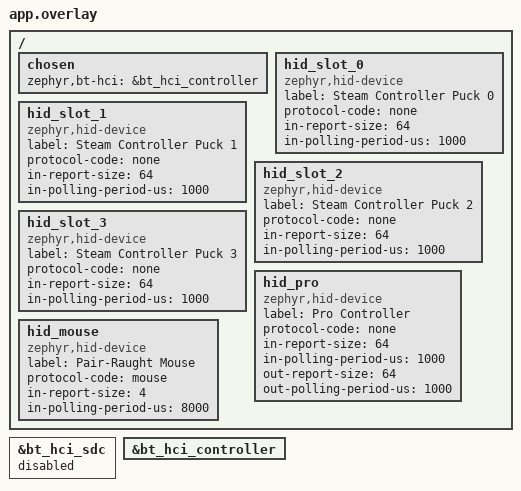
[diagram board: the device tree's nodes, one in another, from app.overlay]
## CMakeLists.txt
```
cmake_minimum_required(VERSION 3.20.0)

find_package(Zephyr REQUIRED HINTS $ENV{ZEPHYR_BASE})
project(switch2_ll)

target_sources(app PRIVATE src/main.c src/switch2_gatt.c src/switch2_memory.c
                          src/switch2_store.c src/rf_radio.c
                          src/puck_usb.c src/puck_hid.c
                          src/rf_link.c src/puck_input.c src/switch_pro.c
                          src/switch_pro_usb.c src/puck_trace.c
                          src/puck_settings.c
                          src/puck_rumble.c src/puck_webdisk.c
                          src/puck_melody.c)

# The console's LL_ENC_REQ carries EDIV=0/Rand=0 -- an out-of-band key agreed
# over GATT, not via SMP -- so the derived LTK has to be pushed straight into
# the host's key store. bt_keys_get_addr()/bt_keys_add_type() are host-internal
# with no public equivalent, so the host directory is on the include path.
# Reassess if a supported API for injecting an out-of-band LTK ever appears.
target_include_directories(app PRIVATE $ENV{ZEPHYR_BASE}/subsys/bluetooth/host)
```

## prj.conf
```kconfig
# Milestone 1: prove the nRF52840 can ACCEPT and HOLD the Switch 2's 5 ms
# connection interval. Nothing else -- no GATT server, no protocol.
#
# The Switch 2 opens controller connections with a CONNECT_IND carrying
# interval=4 (5.00 ms). That is below the Bluetooth spec floor of 6 units
# (7.5 ms), so Nordic's closed SoftDevice silently refuses to join: measured
# on air, 213 CONNECT_INDs at interval=4 went completely unanswered while the
# single interval=12 (15 ms) offer connected and ran for 33 s.
#
# Zephyr's software controller applies the same rule, but in source we can
# edit -- see patches/ull_peripheral-accept-5ms.patch.

CONFIG_BT=y
CONFIG_BT_PERIPHERAL=y
CONFIG_BT_DEVICE_NAME="Joy-Con 2 (R)"

# ---- Attribute table -----------------------------------------------------
# The console writes 0x000F and 0x0010 by hardcoded handle, so the table's
# POSITION matters as much as its content -- see src/switch2_gatt.c.
#
# CONFIG_BT_GATT_CACHING adds Database Hash / Client Supported Features
# attributes ahead of ours and would shift every handle. Off, so the layout is
# ours to control and stays stable across boots.
CONFIG_BT_GATT_CACHING=n

# Services are registered at runtime so the ORDER is ours, not the linker's --
# measured: static definition put the bd28x service first and threw the report
# channel seven handles off. See the comment above switch2_gatt_init().
CONFIG_BT_GATT_DYNAMIC_DB=y

# ---- Encryption ----------------------------------------------------------
# SMP is enabled for its KEY STORE, not to do any pairing.
#
# The console never runs an SMP pairing over this link. Its LL_ENC_REQ carries
# EDIV=0 and Rand=0 -- an out-of-band key -- so the GATT PAIR ceremony IS the
# key agreement, and we derive the LTK ourselves from the 0x15/0x04 exchange.
# What Zephyr provides is bt_smp_request_ltk(), which answers the controller's
# LTK request from conn->le.keys when EDIV and Rand are both zero and the key is
# typed BT_KEYS_LTK_P256. So the derived key is injected into that store the
# moment it exists -- see derive_link_key() in switch2_gatt.c.
#
# Without this the handshake completes in full and the link then dies with
# reason=0x22 (LL Response Timeout), because the console asks to encrypt and
# nothing can answer.
CONFIG_BT_SMP=y
CONFIG_BT_MAX_PAIRED=1
CONFIG_BT_SETTINGS=n

# ---- Link-key persistence -------------------------------------------------
# The Switch 2 drops dock power when it sleeps, and the puck is powered from
# that port, so EVERY wake attempt starts from a cold boot. The console does not
# re-pair on a reconnect -- it sends LL_ENC_REQ expecting the key it stored at
# registration. Measured without persistence: the console finds us on its own,
# opens a 5 ms link, and we answer LL_REJECT_EXT_IND error 0x06 (PIN or Key
# Missing), after which it terminates with 0x13, in a loop.
#
# NVS on the board's 32 KB storage_partition (0xec000). BT_SETTINGS stays off:
# we are not using Zephyr's bonding, only storing the one out-of-band key --
# see src/switch2_store.c.
CONFIG_FLASH=y
CONFIG_FLASH_MAP=y
CONFIG_NVS=y
CONFIG_MPU_ALLOW_FLASH_WRITE=y
# REQUIRED, and its absence is silent: nvs_mount() needs the sector size, which
# switch2_store.c asks for with flash_get_page_info_by_offs(). Without page
# layout support that call returns -ENOTSUP, the mount fails, and the only
# symptom is that nothing is ever persisted.
CONFIG_FLASH_PAGE_LAYOUT=y

# ATT MTU 512 -- matched to the old stack, which is ground truth for a link the
# console was willing to proceed on.
#
# The console sends Exchange MTU Request with Client Rx MTU = 512. The old
# Bluefruit build answered 512 and the console immediately began service
# discovery (Read By Group Type 0x0001-0xFFFF). This build answered 247 and the
# console sent nothing further -- measured, the MTU exchange was the LAST ATT
# traffic of the entire connection, two frames and then silence.
#
# BT_BUF_ACL_RX_SIZE must cover the full L2CAP SDU plus its 4-byte header,
# because reassembly needs one contiguous buffer; TX is fragmented to the
# controller's data length so it does not.
CONFIG_BT_L2CAP_TX_MTU=512
CONFIG_BT_BUF_ACL_RX_SIZE=516
CONFIG_BT_BUF_ACL_TX_SIZE=251
CONFIG_BT_ATT_PREPARE_COUNT=2

# Use Zephyr's OPEN software link layer, not Nordic's SoftDevice Controller.
# The SDC is a binary blob and enforces the 7.5 ms floor where we cannot reach
# it. Selection is done in the devicetree overlay; this is belt and braces.
CONFIG_BT_LL_SW_SPLIT=y

# The console never subscribes anything in this test, but it does run a link
# layer feature exchange immediately after CONNECT_IND -- that exchange
# completing is the pass condition.
CONFIG_BT_CTLR_DATA_LENGTH_MAX=251
CONFIG_BT_CTLR_PHY_2M=y

# Let the CONSOLE choose the connection interval -- do not negotiate.
#
# Zephyr defaults to BT_PERIPHERAL_PREF_MIN_INT=24 (30 ms) and automatically
# asks the central for it shortly after connecting. Measured 2026-08-15: the
# Switch 2 connected at interval=12 (15 ms) and then ACCEPTED our 30 ms request
# at +5 s. That is the opposite of what this test needs -- the whole point is to
# see the console push its own 5 ms interval at us and find out whether the
# patched link layer takes it. The Arduino firmware did no negotiation at all,
# and that is the configuration in which the console was observed demanding
# 5 ms, so match it.
CONFIG_BT_GAP_AUTO_UPDATE_CONN_PARAMS=n

# USB CDC console: DO NOT enable a USB stack here. The board's
# Kconfig.defconfig already sources boards/common/usb/Kconfig.cdc_acm_serial
# which selects USB_DEVICE_STACK_NEXT and initialises CDC ACM at boot. Setting
# CONFIG_USB_DEVICE_STACK=y as well builds BOTH stacks and the link fails with
# "multiple definition of __device_dts_ord_104".
#
# That file also sets LOG_PROCESS_THREAD_STARTUP_DELAY_MS=4000, so the log
# waits for the port to enumerate before emitting.

# CRITICAL for this board. The upstream promicro_nrf52840 board definition
# defaults to CONFIG_CLOCK_CONTROL_NRF_K32SRC_XTAL, i.e. an external 32.768 kHz
# crystal -- which these cheap Pro Micro clones do not have. With no LFCLK the
# BLE controller can never schedule a radio event, so bt_enable() and
# bt_le_adv_start() both return success and NOTHING is transmitted. Measured:
# firmware alive and heartbeating over USB, host reporting
# an identity and "advertising ... wake mode", while
# a 30 s sniffer survey saw six other advertisers and zero packets from us.
# The internal RC oscillator costs accuracy (500 ppm vs ~20 ppm) but works.
CONFIG_CLOCK_CONTROL_NRF_K32SRC_RC=y
CONFIG_CLOCK_CONTROL_NRF_K32SRC_500PPM=y

# ---- USB: we are a Valve Steam Controller dongle -------------------------
# The board's cdc_acm_serial helper builds a USB device automatically so the
# console works with no app code, but it hardcodes its own VID/PID and, in its
# own words, "only registers the first CDC-ACM instance" and is "intended for
# use only in applications where no other USB features are required". We need
# 28DE:1304 and five interfaces, so it is turned off and src/puck_usb.c builds
# the device instead -- including the CDC console, which would otherwise vanish.
# TEMPORARILY REVERTED to the board's auto-init while the custom device is
# debugged. Building our own context (28DE:1304 + 4 HID + CDC) made the board
# enumerate as "Unknown USB Device (Port Reset Failed)" -- no console, and
# recovery costs a physical double-tap on reset. Debugging that blind is not
# worth a button press per guess, so the console comes first and the composite
# device gets rebuilt against a working one.
CONFIG_CDC_ACM_SERIAL_INITIALIZE_AT_BOOT=n
CONFIG_USBD_HID_SUPPORT=y

CONFIG_LOG=y
CONFIG_PRINTK=y

# Deliberately NOT CONFIG_LOG_MODE_IMMEDIATE. Immediate mode logs synchronously
# from the calling context, which on a CDC console blocks when the host is slow
# or absent -- that is exactly the 84 ms main-loop stall that distorted every
# measurement taken with the Arduino firmware. Deferred logging keeps the
# radio's timing honest, which matters more here than log latency.
#
# BUT take printk back out of the deferred path. CONFIG_LOG_PRINTK defaults to y,
# which routes printk() through the very same buffer, so "use printk instead of
# LOG_INF for diagnostics" bought nothing: measured 2026-08-15, an entire boot's
# worth of printk output AND five heartbeats were discarded, hiding a hard
# bt_le_adv_start() -ENOMEM behind a log that jumped from 0.003 s to 30 s. With
# this off, printk writes straight to the console driver and cannot be dropped.
# It blocks, so keep it to diagnostics and out of the radio's hot path.
CONFIG_LOG_PRINTK=n

# 1024 bytes is roughly ten messages -- less than one boot. The messages that
# matter here (bt_hci_core's "opcode 0x%04x status 0x%02x") arrive while USB is
# still enumerating, so the buffer has to survive the whole startup backlog.
CONFIG_LOG_BUFFER_SIZE=4096

# Real console input. uart_poll_in() never sees a byte on a CDC ACM console
# (interrupt driven), which silently broke the reboot-to-bootloader key.
CONFIG_CONSOLE_SUBSYS=y
CONFIG_CONSOLE_GETCHAR=y

# console_getchar() defaults to a SIXTEEN byte ring, which is fine for single
# keypresses and silently loses characters the moment anything types a line.
# The config protocol sends whole commands at once -- "$set mouse.speed 8" is
# nineteen characters -- and the overflow showed up as commands that simply
# never executed, with the tail of one line turning up glued to the next.
# Zephyr own help text names the case: "you may need to increase it e.g. to
# support large host-side clipboard pastes".
CONFIG_CONSOLE_GETCHAR_BUFSIZE=256

# sys_reboot() -- used to reboot into a one-shot armed USB attempt (TEMPORARY,
# see the scaffolding note in switch2_store.c).
CONFIG_REBOOT=y

# The config page as a USB drive, in dongle mode only. The volume is
# synthesised per sector by puck_webdisk.c, so no disk driver and no
# filesystem are needed -- and no RAM is spent on either.
CONFIG_USBD_MSC_CLASS=y
CONFIG_DISK_ACCESS=y
```

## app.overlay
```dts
/*
 * Select Zephyr's open software link layer instead of Nordic's SoftDevice
 * Controller.
 *
 * nrf52840.dtsi ships with:
 *     chosen { zephyr,bt-hci = &bt_hci_sdc; }
 *     bt_hci_sdc        (nordic,bt-hci-sdc)         status = "okay"
 *     bt_hci_controller (zephyr,bt-hci-ll-sw-split) status = "disabled"
 *
 * The SDC is a binary blob, so its 7.5 ms connection-interval floor cannot be
 * relaxed. The software controller is source we can patch, which is the entire
 * reason for this port.
 */

/ {
	chosen {
		zephyr,bt-hci = &bt_hci_controller;
	};
};

&bt_hci_sdc {
	status = "disabled";
};

&bt_hci_controller {
	status = "okay";
};

/*
 * The Valve dongle's four HID interfaces.
 *
 * A real Steam Controller dongle exposes ONE HID interface per bond slot, and
 * Steam treats each as an independent controller -- interface N owns slot N.
 * That is also how pairing happens: Steam drives the control channel over
 * feature reports (report IDs 0x01/0x02, 63 bytes) on these interfaces, and the
 * resulting bond record is what the RF layer later beacons for. There is no
 * over-the-air pairing, so without these four interfaces no controller can ever
 * be bonded.
 *
 * in-report-size 64 covers the largest input report in PUCK_HID_DESC (0x45 is
 * 0x2D=45 bytes, plus the report ID). 1 ms polling matches the dongle, which
 * Steam's input path expects.
 */
/ {
	hid_slot_0: hid_slot_0 {
		compatible = "zephyr,hid-device";
		label = "Steam Controller Puck 0";
		protocol-code = "none";
		in-report-size = <64>;
		in-polling-period-us = <1000>;
	};

	hid_slot_1: hid_slot_1 {
		compatible = "zephyr,hid-device";
		label = "Steam Controller Puck 1";
		protocol-code = "none";
		in-report-size = <64>;
		in-polling-period-us = <1000>;
	};

	hid_slot_2: hid_slot_2 {
		compatible = "zephyr,hid-device";
		label = "Steam Controller Puck 2";
		protocol-code = "none";
		in-report-size = <64>;
		in-polling-period-us = <1000>;
	};

	hid_slot_3: hid_slot_3 {
		compatible = "zephyr,hid-device";
		label = "Steam Controller Puck 3";
		protocol-code = "none";
		in-report-size = <64>;
		in-polling-period-us = <1000>;
	};

	/*
	 * The Pro Controller interface, used INSTEAD of the four above when the
	 * puck boots in Pro Controller mode.
	 *
	 * It needs an interrupt OUT endpoint, which the Steam interfaces do not
	 * have: the console sends its handshake and subcommands (reports 0x01,
	 * 0x10, 0x80) on the OUT pipe, and without one they would only ever
	 * arrive as control-pipe SET_REPORTs -- which is not where a real Pro
	 * Controller receives them.
	 *
	 * 1 ms polling matches what the Arduino build sets (setPollInterval(1)).
	 */
	hid_pro: hid_pro {
		compatible = "zephyr,hid-device";
		label = "Pro Controller";
		protocol-code = "none";
		in-report-size = <64>;
		in-polling-period-us = <1000>;
		out-report-size = <64>;
		out-polling-period-us = <1000>;
	};

	/*
	 * A plain boot-protocol MOUSE, carried alongside the Pro Controller.
	 *
	 * The Switch 2 supports USB mice, so the trackpads can drive one -- but
	 * whether the console still binds a Pro Controller that has a mouse
	 * sitting beside it is UNKNOWN. Adding an interface to a working device
	 * is exactly what COMBO did, and Steam misbehaved with it. A console has
	 * no reason to claim a mouse the way Steam claimed a gamepad, but that
	 * was true of Steam too until it was tried.
	 *
	 * 4-byte report: buttons, dx, dy, wheel.
	 */
	hid_mouse: hid_mouse {
		compatible = "zephyr,hid-device";
		label = "Pair-Raught Mouse";
		protocol-code = "mouse";
		in-report-size = <4>;
		in-polling-period-us = <8000>;
	};
};
```

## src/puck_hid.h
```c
/*
 * The Valve dongle HID interfaces. One per bond slot, and the path Steam
 * pairs a Steam Controller through.
 */

#ifndef PUCK_HID_H
#define PUCK_HID_H

/* Register the report descriptor and callbacks on every HID interface. MUST run
 * before usbd_init(): until this is called the HID class contributes no
 * interface descriptor and device assembly fails with -EINVAL.
 */
int puck_hid_register_all(void);

/*
 * Reload the Steam bonds from NVS. Needed in BOTH USB modes: the RF layer
 * derives each slot session address from its bond, so without this the puck
 * never beacons and no controller input arrives, in Pro Controller mode that
 * looks like a pad that enumerates perfectly with every button dead.
 */
void puck_hid_restore_bonds(void);

/*
 * This slot's Steam bond record, or NULL if the slot is empty.
 *
 * [0..4] proteus uuid, [4..8] ibex uuid, [8..24] the controller's 16-byte
 * serial. The RF layer needs the two uuids: they go in the E1 beacon so the
 * controller can recognise a puck it is bonded to, and the ibex uuid seeds this
 * slot's unique session address.
 */
const uint8_t *puck_hid_bond(int slot);

/*
 * Push one input report to Steam on this slot's interface.
 *
 * Steam decides a controller is CONNECTED by receiving these, not by the 0xB4
 * connection-state answer alone, so nothing appears online until the RF layer
 * starts forwarding the controller's 0x45/0x42 reports through here.
 */
int puck_hid_send_input(int slot, uint8_t rid, const uint8_t *data,
			uint16_t len);

/*
 * Push each slot's connection state to Steam (report 0x79). Call periodically.
 *
 * Steam does not notice a controller going away by itself. Without this it
 * keeps listing one that has been switched off, and a later re-pair then shows
 * up as a SECOND controller alongside the stale entry.
 */
void puck_hid_conn_task(void);

/*
 * Per-slot state of the outgoing report path, whether the host is draining
 * this interface, and how many reports were dropped because it was not.
 */
void puck_hid_dump_tx(void);

/* A power-off was relayed to this slot (the Steam+Y chord), so force a clean
 * disconnect and hold it through the controller's post-off report tail.
 */
void puck_hid_note_power_off(int slot);

#endif /* PUCK_HID_H */
```

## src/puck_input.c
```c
/*
 * Decode the Steam Controller's input report.
 *
 * Field offsets are relative to rep[2], the buttons' low byte, matching the
 * Arduino build's s16off()/u16off() decoders so the two firmwares read the same
 * wire format the same way:
 *
 *   +0   buttons u32 LE
 *   +4   left trigger  u16
 *   +6   right trigger u16
 *   +8   left stick  X s16   +10  left stick  Y s16
 *   +12  right stick X s16   +14  right stick Y s16
 *   +22  right pad X s16     +24  right pad Y s16
 *   (IMU: accel @0x22, gyro @0x28 from the report start)
 *
 * Report id 0x45 is the legacy form and 0x42 the one shipped in the mid-2026
 * controller update; bytes [0..45] are byte-for-byte identical between them, so
 * both decode through this one path.
 */

#include <zephyr/kernel.h>
#include <string.h>

#include "puck_input.h"

static struct puck_input g_in[PUCK_HID_SLOTS];

static int s16off(const uint8_t *r, int off)
{
	int v = r[2 + off] | (r[2 + off + 1] << 8);

	return (v & 0x8000) ? v - 0x10000 : v;
}

static int u16off(const uint8_t *r, int off)
{
	return r[2 + off] | (r[2 + off + 1] << 8);
}

/*
 * The controller's trigger u16 tops out near HALF scale (~0x8000) on a full
 * pull, so a straight >>8 reads only ~0x80 and the host sees a half-pressed
 * trigger. Scale by two and saturate.
 */
static uint8_t trig_u8(int v16)
{
	int v = v16 >> 7;

	return (uint8_t)(v > 255 ? 255 : v);
}

void puck_input_update(int slot, const uint8_t *rep)
{
	struct puck_input *in;

	if (slot < 0 || slot >= PUCK_HID_SLOTS) {
		return;
	}
	in = &g_in[slot];

	in->buttons = (uint32_t)rep[2] | ((uint32_t)rep[3] << 8) |
		      ((uint32_t)rep[4] << 16) | ((uint32_t)rep[5] << 24);

	in->lt = trig_u8(u16off(rep, 4));
	in->rt = trig_u8(u16off(rep, 6));

	in->lx = (int16_t)s16off(rep, 8);
	in->ly = (int16_t)s16off(rep, 10);
	in->rx = (int16_t)s16off(rep, 12);
	in->ry = (int16_t)s16off(rep, 14);

	/* Right trackpad, absolute. Only meaningful while TB_RPADT says a
	 * finger is down. The coordinates hold their last value on release,
	 * so anything reading them must gate on the touch bit or it will see a
	 * jump the next time a finger lands somewhere else.
	 */
	in->rpx = (int16_t)s16off(rep, 22);
	in->rpy = (int16_t)s16off(rep, 24);

	/* IMU: accel at 32/34/36, gyro at 38/40/42 (PROTOCOL.md section 8, via
	 * the Arduino build imuFrom45). Raw sensor frame, whoever consumes it
	 * does the axis permutation, because each output mode wants a different
	 * one.
	 */
	in->ax = (int16_t)s16off(rep, 32);
	in->ay = (int16_t)s16off(rep, 34);
	in->az = (int16_t)s16off(rep, 36);
	in->gx = (int16_t)s16off(rep, 38);
	in->gy = (int16_t)s16off(rep, 40);
	in->gz = (int16_t)s16off(rep, 42);

	in->valid = true;
}

bool puck_input_get(int slot, struct puck_input *out)
{
	if (slot < 0 || slot >= PUCK_HID_SLOTS || !g_in[slot].valid) {
		return false;
	}
	*out = g_in[slot];
	return true;
}

void puck_input_dump(int slot)
{
	struct puck_input in;

	if (!puck_input_get(slot, &in)) {
		printk("input: slot %d has no report yet\n", slot);
		return;
	}

	printk("input slot%d: btn=%08x L(%6d,%6d) R(%6d,%6d) LT=%3u RT=%3u\n",
	       slot, (unsigned)in.buttons, in.lx, in.ly, in.rx, in.ry, in.lt,
	       in.rt);
}
```

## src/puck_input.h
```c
/*
 * The controller's decoded input, shared by every output mode.
 *
 * The RF layer fills this from the Steam Controller's 0x45/0x42 report; the
 * output modes read it. One source of truth, mirroring g_in[] in the Arduino
 * build: a mode never parses the wire format itself.
 *
 * This is deliberately independent of how the puck is presenting itself. The
 * puck's job in RF mode is to be a USB controller to whatever it is plugged
 * into (a Switch 2 as a Pro Controller, or a PC through the Steam dongle
 * interfaces) and all of those consume the same decoded state.
 */

#ifndef PUCK_INPUT_H
#define PUCK_INPUT_H

#include <stdbool.h>
#include <stdint.h>

#include "puck_usb.h"

/*
 * Steam Controller button bits, as they arrive in the report's 32-bit button
 * word. Names and positions copied from the Arduino build's triton.h.
 */
#define TB_A       0x00000001u
#define TB_B       0x00000002u
#define TB_X       0x00000004u
#define TB_Y       0x00000008u
#define TB_QAM     0x00000010u	/* the "three dots" button */
#define TB_R3      0x00000020u
#define TB_VIEW    0x00000040u
#define TB_R4      0x00000080u	/* back paddles */
#define TB_R5      0x00000100u
#define TB_RB      0x00000200u
#define TB_DDN     0x00000400u
#define TB_DRT     0x00000800u
#define TB_DLF     0x00001000u
#define TB_DUP     0x00002000u
#define TB_MENU    0x00004000u
#define TB_L3      0x00008000u
#define TB_STEAM   0x00010000u
#define TB_L4      0x00020000u
#define TB_L5      0x00040000u
#define TB_LB      0x00080000u
#define TB_RPADT   0x00200000u	/* right pad touch */
#define TB_RPADC   0x00400000u	/* right pad click */
#define TB_R2      0x00800000u	/* full trigger pull, digital */
#define TB_LPADT   0x02000000u
#define TB_LPADC   0x04000000u
#define TB_L2      0x08000000u

/* All four back paddles, the mode-switch chord guard. */
#define CHORD_BACK4 (TB_R4 | TB_L4 | TB_R5 | TB_L5)

/* Analog-trigger fraction of 0xFF at which a digital ZL/ZR trips. */
#define TRIG_ON 40

struct puck_input {
	uint32_t buttons;	/* TB_* bits */
	int16_t lx, ly;		/* left stick, signed 16-bit */
	int16_t rx, ry;		/* right stick */
	uint8_t lt, rt;		/* triggers, full-scale 0..255 */
	int16_t rpx, rpy;	/* right trackpad, absolute; see TB_RPADT */
	int16_t ax, ay, az;	/* accelerometer, raw sensor frame */
	int16_t gx, gy, gz;	/* gyroscope, raw sensor frame */
	bool valid;		/* a report has been decoded for this slot */
};

/* Decode one 0x45/0x42 report body into `slot`'s state. `rep` points at the
 * report id, so field offsets are relative to rep[2] exactly as in the
 * Arduino build's decoders.
 */
void puck_input_update(int slot, const uint8_t *rep);

/* Read a slot's current state. Returns false if nothing has been decoded. */
bool puck_input_get(int slot, struct puck_input *out);

/* Print one slot's live input. Bound to console key 'i'. */
void puck_input_dump(int slot);

#endif /* PUCK_INPUT_H */
```

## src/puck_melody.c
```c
/*
 * Haptic tones and the chimes. See puck_melody.h.
 */

#include <zephyr/kernel.h>
#include <errno.h>
#include <stdarg.h>
#include <string.h>

#include "puck_melody.h"
#include "puck_settings.h"
#include "rf_link.h"
#include "switch2_store.h"

/*
 * Output report 0x83, nine bytes:
 *
 *   tone  [haptic][gain][freq Hz, le16][FF 7F][00 00 00]
 *   stop  [haptic][80][00 00][00 80][00 00 00]
 *
 * gain is signed and 0x00 is medium. SteamHapticsSinger warns that full gain
 * may damage the actuators, so nothing here goes above medium.
 */
#define HAPTIC_RID	0x83
#define STOP_SHOTS	3

void puck_haptic_tone(int slot, uint8_t haptic, uint16_t hz, int8_t gain)
{
	uint8_t p[9] = { haptic, 0, hz & 0xFF, hz >> 8, 0xFF, 0x7F };

	if (gain > PUCK_HAPTIC_GAIN_MEDIUM) {
		gain = PUCK_HAPTIC_GAIN_MEDIUM;
	}
	p[1] = (uint8_t)gain;

	/* Once, the way Steam's own haptics are relayed. Whether a repeat
	 * restarts the waveform is unknown, and a lost tone is a missed note,
	 * where a lost stop would be a stuck one.
	 */
	rf_link_relay(slot, HAPTIC_RID, p, sizeof(p), 1);
}

void puck_haptic_stop(int slot, uint8_t haptic)
{
	uint8_t p[9] = { haptic, 0x80, 0x00, 0x00, 0x00, 0x80 };

	rf_link_relay(slot, HAPTIC_RID, p, sizeof(p), STOP_SHOTS);
}

/*
 * The haptics a note may name, the default first. The right rumble motor is
 * the default because it is what the chimes were tuned on: the trackpads were
 * too quiet on a real wake, and both rumble motors at once sounded distorted.
 */
static const uint8_t CHANNELS[] = {
	PUCK_HAPTIC_RUMBLE_R,
	PUCK_HAPTIC_RUMBLE_L,
	PUCK_HAPTIC_PAD_R,
	PUCK_HAPTIC_PAD_L,
};

size_t puck_chime_channels(const uint8_t **list)
{
	*list = CHANNELS;
	return ARRAY_SIZE(CHANNELS);
}

static bool channel_ok(uint8_t haptic)
{
	for (size_t i = 0; i < ARRAY_SIZE(CHANNELS); i++) {
		if (CHANNELS[i] == haptic) {
			return true;
		}
	}
	return false;
}

/*
 * THE DEFAULT CHIMES, all on the default haptic.
 *
 * Frequencies are whole Hz, which is all the command carries, so each note is
 * within half a hertz of true pitch.
 */
#define NOTE(h, m) { .hz = (h), .ms = (m), .haptic = PUCK_CHIME_CHANNEL_DEFAULT }

static const struct puck_note DEFAULT_WAKE[] = {
	NOTE(1109,  90),	/* C#6 */
	NOTE( 554,  90),	/* C#5 */
	NOTE( 740,  90),	/* F#5 */
	NOTE( 932,  90),	/* A#5 */
	NOTE( 831, 220),	/* G#5 */
};

/* The mode chimes are two notes a fifth apart, so they cannot be mistaken for
 * the wake: falling into the dongle, rising into Pro Controller.
 */
static const struct puck_note DEFAULT_DONGLE[] = {
	NOTE( 831,  90),	/* G#5 */
	NOTE( 554, 220),	/* C#5 */
};

static const struct puck_note DEFAULT_PRO[] = {
	NOTE( 554,  90),	/* C#5 */
	NOTE( 831, 220),	/* G#5 */
};

static const struct {
	const char *name;
	const struct puck_note *notes;
	uint8_t count;
} CHIMES[PUCK_CHIME_COUNT] = {
	[PUCK_CHIME_WAKE]   = { "wake",   DEFAULT_WAKE,   ARRAY_SIZE(DEFAULT_WAKE) },
	[PUCK_CHIME_DONGLE] = { "dongle", DEFAULT_DONGLE, ARRAY_SIZE(DEFAULT_DONGLE) },
	[PUCK_CHIME_PRO]    = { "pro",    DEFAULT_PRO,    ARRAY_SIZE(DEFAULT_PRO) },
};

/*
 * Version 1 records, from before a note named its haptic, when every note
 * played on the right rumble motor. Read at boot and converted, so a chime saved
 * then still plays as it did. The stored length is what tells the two apart.
 */
struct puck_chime_v1 {
	uint8_t version;
	uint8_t count;
	struct {
		uint16_t hz;
		uint16_t ms;
	} notes[PUCK_CHIME_MAX_NOTES];
};

BUILD_ASSERT(sizeof(struct puck_chime_v1) == 66, "version 1 chime layout");
BUILD_ASSERT(sizeof(struct puck_chime) == 98, "version 2 chime layout");

/*
 * The loudest a chime is allowed, which is chime.volume 100. Tuned by ear on
 * the right rumble motor: medium (0) sounded slightly distorted, -16 was clean
 * but a little too quiet, and -8 was right. Volume maps linearly from silent up
 * to this; whether loudness follows gain linearly is not known.
 */
#define CHIME_GAIN_MAX	(-8)

/*
 * How long a stop burst takes to leave. With RF up a slot is polled about every
 * 10.6 ms, so three shots are gone in ~32 ms. The relay holds ONE command per
 * slot and the next one overwrites it, so nothing is queued behind a stop until
 * this has passed.
 */
#define BURST_MS	50

/*
 * The same limit for a single-shot tone: anything queued sooner overwrites it
 * before it goes out. Two polls and some, because the RF thread also blocks
 * while it prints its counters.
 */
#define TONE_GAP_MS	25

static struct puck_chime g_chimes[PUCK_CHIME_COUNT];

/* --- the stored chimes -------------------------------------------------- */

const char *puck_chime_name(int id)
{
	return (id >= 0 && id < PUCK_CHIME_COUNT) ? CHIMES[id].name : NULL;
}

int puck_chime_lookup(const char *name)
{
	for (int id = 0; id < PUCK_CHIME_COUNT; id++) {
		if (!strcmp(name, CHIMES[id].name)) {
			return id;
		}
	}
	return -1;
}

void puck_chime_defaults(int id, struct puck_chime *c)
{
	memset(c, 0, sizeof(*c));
	c->version = PUCK_CHIME_VERSION;
	if (id < 0 || id >= PUCK_CHIME_COUNT) {
		return;
	}
	c->count = CHIMES[id].count;
	memcpy(c->notes, CHIMES[id].notes, c->count * sizeof(c->notes[0]));
}

static int reject(char *err, size_t errlen, const char *fmt, ...)
{
	va_list ap;

	if (err && errlen) {
		va_start(ap, fmt);
		vsnprintk(err, errlen, fmt, ap);
		va_end(ap);
	}
	return -EINVAL;
}

int puck_chime_check(const struct puck_chime *c, char *err, size_t errlen)
{
	uint32_t total = 0;

	if (c->count < 1 || c->count > PUCK_CHIME_MAX_NOTES) {
		return reject(err, errlen, "a chime has 1 to %u notes",
			      PUCK_CHIME_MAX_NOTES);
	}

	for (int i = 0; i < c->count; i++) {
		const struct puck_note *n = &c->notes[i];
		uint16_t ms_min = n->hz ? PUCK_CHIME_MS_MIN
					: PUCK_CHIME_REST_MS_MIN;

		if (n->hz && (n->hz < PUCK_CHIME_HZ_MIN ||
			      n->hz > PUCK_CHIME_HZ_MAX)) {
			return reject(err, errlen,
				      "note %d: %u Hz is outside %u to %u", i + 1,
				      n->hz, PUCK_CHIME_HZ_MIN,
				      PUCK_CHIME_HZ_MAX);
		}
		if (n->hz && !channel_ok(n->haptic)) {
			return reject(err, errlen, "note %d: no haptic %u", i + 1,
				      n->haptic);
		}
		if (n->ms < ms_min || n->ms > PUCK_CHIME_MS_MAX) {
			return reject(err, errlen,
				      "note %d: %u ms is outside %u to %u%s",
				      i + 1, n->ms, ms_min, PUCK_CHIME_MS_MAX,
				      n->hz ? "" : " for a rest");
		}
		total += n->ms;
	}

	if (total > PUCK_CHIME_TOTAL_MS_MAX) {
		return reject(err, errlen, "the chime is %u ms, over the %u limit",
			      total, PUCK_CHIME_TOTAL_MS_MAX);
	}
	return 0;
}

/* One decimal number up to 65535, advancing *s past it. */
static bool parse_u16(const char **s, uint16_t *out)
{
	const char *p = *s;
	uint32_t v = 0;

	if (*p < '0' || *p > '9') {
		return false;
	}
	while (*p >= '0' && *p <= '9') {
		v = v * 10u + (uint32_t)(*p - '0');
		if (v > 0xFFFF) {
			return false;
		}
		p++;
	}
	*out = (uint16_t)v;
	*s = p;
	return true;
}

int puck_chime_parse(const char *s, struct puck_chime *c, char *err,
		     size_t errlen)
{
	memset(c, 0, sizeof(*c));
	c->version = PUCK_CHIME_VERSION;

	for (;;) {
		struct puck_note n = { .haptic = PUCK_CHIME_CHANNEL_DEFAULT };
		uint16_t haptic;

		while (*s == ' ') {
			s++;
		}
		if (!*s) {
			break;
		}
		if (c->count == PUCK_CHIME_MAX_NOTES) {
			return reject(err, errlen, "more than %u notes",
				      PUCK_CHIME_MAX_NOTES);
		}
		if (!parse_u16(&s, &n.hz) || *s != ':') {
			return reject(err, errlen,
				      "note %u: expected hz:ms or hz:ms:haptic",
				      c->count + 1);
		}
		s++;
		if (!parse_u16(&s, &n.ms)) {
			return reject(err, errlen,
				      "note %u: expected hz:ms or hz:ms:haptic",
				      c->count + 1);
		}
		if (*s == ':') {
			s++;
			if (!parse_u16(&s, &haptic) || haptic > 0xFF) {
				return reject(err, errlen,
					      "note %u: expected a haptic after "
					      "the second colon", c->count + 1);
			}
			n.haptic = (uint8_t)haptic;
		}
		if (*s && *s != ' ') {
			return reject(err, errlen,
				      "note %u: expected hz:ms or hz:ms:haptic",
				      c->count + 1);
		}
		c->notes[c->count++] = n;
	}

	return puck_chime_check(c, err, errlen);
}

/* A stored chime, converted from version 1 if that is what was saved. */
static bool load_stored(int id, struct puck_chime *c)
{
	struct puck_chime_v1 old;

	if (switch2_store_load_chime(id, c, sizeof(*c))) {
		return true;
	}
	if (!switch2_store_load_chime(id, &old, sizeof(old)) || old.version != 1) {
		return false;
	}

	memset(c, 0, sizeof(*c));
	c->version = PUCK_CHIME_VERSION;
	c->count = MIN(old.count, PUCK_CHIME_MAX_NOTES);
	for (int i = 0; i < c->count; i++) {
		c->notes[i].hz = old.notes[i].hz;
		c->notes[i].ms = old.notes[i].ms;
		c->notes[i].haptic = PUCK_CHIME_CHANNEL_DEFAULT;
	}
	printk("chime: %s was saved before notes had a haptic: all on the "
	       "default\n", CHIMES[id].name);
	return true;
}

void puck_chime_init(void)
{
	struct puck_chime stored;

	for (int id = 0; id < PUCK_CHIME_COUNT; id++) {
		puck_chime_defaults(id, &g_chimes[id]);

		if (!load_stored(id, &stored)) {
			continue;	/* never edited: the default */
		}

		/*
		 * A record this build would refuse came from one with other
		 * limits. Playing notes the page could never have sent is worse
		 * than the default.
		 */
		if (stored.version != PUCK_CHIME_VERSION ||
		    puck_chime_check(&stored, NULL, 0)) {
			printk("chime: stored %s chime is not usable: using the "
			       "default\n", CHIMES[id].name);
			continue;
		}

		g_chimes[id] = stored;
		printk("chime: %s, %u notes loaded\n", CHIMES[id].name,
		       stored.count);
	}
}

const struct puck_chime *puck_chime_get(int id)
{
	return (id >= 0 && id < PUCK_CHIME_COUNT) ? &g_chimes[id] : NULL;
}

int puck_chime_set(int id, const struct puck_chime *c)
{
	if (id < 0 || id >= PUCK_CHIME_COUNT || puck_chime_check(c, NULL, 0)) {
		return -EINVAL;
	}

	g_chimes[id] = *c;
	g_chimes[id].version = PUCK_CHIME_VERSION;
	return switch2_store_save_chime(id, &g_chimes[id], sizeof(g_chimes[id]));
}

int8_t puck_chime_gain(void)
{
	int32_t span = CHIME_GAIN_MAX - PUCK_HAPTIC_GAIN_SILENT;
	int32_t vol = MIN(g_cfg.chime_volume, 100);

	return (int8_t)(PUCK_HAPTIC_GAIN_SILENT + (span * vol + 50) / 100);
}

/* --- the player --------------------------------------------------------- */

/*
 * A chime is planned into commands before it plays, one per relay, because the
 * relay carries one at a time. Each command waits `ms` before the next is sent.
 */
enum { ACT_TONE, ACT_STOP, ACT_WAIT };

struct action {
	uint8_t op;
	uint8_t haptic;
	uint16_t hz;
	uint16_t ms;
};

/* Lead and closing stops on every haptic, and at most two commands a note. */
#define MAX_ACTIONS	(2 * ARRAY_SIZE(CHANNELS) + 2 * PUCK_CHIME_MAX_NOTES)

static atomic_t g_busy;
static int g_slot;
static int8_t g_gain;
static struct action g_actions[MAX_ACTIONS];
static int g_nactions;
static int g_next;
static void (*g_done)(void);

static void step_fn(struct k_work *work);
static K_WORK_DELAYABLE_DEFINE(g_step_work, step_fn);

static void push(uint8_t op, uint8_t haptic, uint16_t hz, int ms)
{
	if (g_nactions < MAX_ACTIONS) {
		g_actions[g_nactions++] = (struct action){
			.op = op, .haptic = haptic, .hz = hz,
			.ms = (uint16_t)MAX(ms, 1),
		};
	}
}

static void plan(const struct puck_chime *c)
{
	uint32_t used = 0;	/* a bit per haptic that plays a note */
	int sounding = -1;	/* the haptic still playing, if any */
	int count = MIN(c->count, PUCK_CHIME_MAX_NOTES);

	g_nactions = 0;

	for (int i = 0; i < count; i++) {
		if (c->notes[i].hz) {
			used |= BIT(c->notes[i].haptic);
		}
	}

	/* Stops lead, on every haptic the chime uses. SteamHapticsSinger found
	 * the rumble motors could reboot the controller on a note with nothing
	 * stopped before it.
	 */
	for (int h = 0; h < 8; h++) {
		if (used & BIT(h)) {
			push(ACT_STOP, h, 0, BURST_MS);
		}
	}

	for (int i = 0; i < count; i++) {
		const struct puck_note *n = &c->notes[i];

		if (n->hz == 0) {
			/* A rest stops whatever is playing, and waits out the
			 * burst like any stop. The rest minimum covers it.
			 */
			if (sounding >= 0) {
				push(ACT_STOP, sounding, 0, MAX(n->ms, BURST_MS));
				sounding = -1;
			} else {
				push(ACT_WAIT, 0, 0, n->ms);
			}
		} else if (sounding < 0 || sounding == n->haptic) {
			/* The same haptic, or nothing playing: back to back,
			 * with no stop between notes. A new tone replaces the one
			 * playing, which is how SteamHapticsSinger plays too.
			 */
			push(ACT_TONE, n->haptic, n->hz, n->ms);
			sounding = n->haptic;
		} else {
			/* Another haptic. Start the new note first so it lands
			 * on time, then stop the old one once that tone has gone
			 * out. The stop is a burst and nothing may be queued
			 * behind it until it has left, so a note shorter than
			 * the two together is stretched to fit.
			 */
			push(ACT_TONE, n->haptic, n->hz, TONE_GAP_MS);
			push(ACT_STOP, sounding, 0,
			     MAX((int)n->ms - TONE_GAP_MS, BURST_MS));
			sounding = n->haptic;
		}
	}

	/* Stops close, on every haptic used, which also catches a mid-chime stop
	 * that a later command overwrote.
	 */
	for (int h = 0; h < 8; h++) {
		if (used & BIT(h)) {
			push(ACT_STOP, h, 0, BURST_MS);
		}
	}
}

/*
 * One command per run, paced by the work queue rather than by sleeping, so the
 * chime never holds up anything else queued there.
 */
static void step_fn(struct k_work *work)
{
	const struct action *a;

	ARG_UNUSED(work);

	if (g_next >= g_nactions) {
		void (*done)(void) = g_done;

		atomic_set(&g_busy, 0);
		if (done) {
			done();
		}
		return;
	}

	a = &g_actions[g_next++];
	if (a->op == ACT_TONE) {
		puck_haptic_tone(g_slot, a->haptic, a->hz, g_gain);
	} else if (a->op == ACT_STOP) {
		puck_haptic_stop(g_slot, a->haptic);
	}
	k_work_schedule(&g_step_work, K_MSEC(a->ms));
}

int puck_melody_play(int slot, const struct puck_chime *c, int8_t gain,
		     void (*done)(void))
{
	if (!atomic_cas(&g_busy, 0, 1)) {
		return -EBUSY;
	}

	g_slot = slot;
	g_gain = gain;
	g_done = done;
	plan(c);
	g_next = 0;
	printk("chime: slot%d, %u notes as %d commands, gain %d\n", slot,
	       c->count, g_nactions, gain);
	k_work_schedule(&g_step_work, K_NO_WAIT);
	return 0;
}

int puck_melody_play_chime(int id, int slot, void (*done)(void))
{
	if (id < 0 || id >= PUCK_CHIME_COUNT) {
		return -EINVAL;
	}
	return puck_melody_play(slot, &g_chimes[id], puck_chime_gain(), done);
}

int puck_melody_play_wake(int slot, void (*done)(void))
{
	return puck_melody_play_chime(PUCK_CHIME_WAKE, slot, done);
}

bool puck_melody_busy(void)
{
	return atomic_get(&g_busy) != 0;
}
```

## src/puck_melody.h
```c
/*
 * Tones on the Steam Controller's haptics, and the chimes the puck plays.
 *
 * The controller plays a pitch on any of its four haptics when sent output
 * report 0x83, the command SteamHapticsSinger uses to play notes on a Steam
 * Controller (2026) (BSD 3-clause, github.com/CrazyCritic89/SteamHapticsSinger).
 * The puck relays it over RF like any other haptic. Tones on a trackpad and on
 * a rumble motor have both been heard through it, at the same pitch and with a
 * different tonal quality.
 */

#ifndef PUCK_MELODY_H
#define PUCK_MELODY_H

#include <stdint.h>
#include <stdbool.h>
#include <stddef.h>

/* Which haptic plays a tone. There is no haptic 2. */
#define PUCK_HAPTIC_PAD_L	0
#define PUCK_HAPTIC_PAD_R	1
#define PUCK_HAPTIC_RUMBLE_L	3
#define PUCK_HAPTIC_RUMBLE_R	4

/* Gain is signed: 0 is medium and -128 is silent. */
#define PUCK_HAPTIC_GAIN_MEDIUM	0
#define PUCK_HAPTIC_GAIN_SILENT	(-128)

/*
 * Start a tone on one haptic. It plays until stopped. Gain above medium is
 * clamped to medium: SteamHapticsSinger warns full gain may damage actuators.
 */
void puck_haptic_tone(int slot, uint8_t haptic, uint16_t hz, int8_t gain);

/* Stop one haptic. Sent as a burst, because a lost stop leaves it playing. */
void puck_haptic_stop(int slot, uint8_t haptic);

/*
 * THE CHIMES, each stored as its own record and edited from the config page.
 * The limits are both what the firmware accepts and what the page is told
 * ($chime <name> get), so the page never carries its own copy.
 *
 * hz 0 is a rest. A rest is played as a stop burst, so it has a longer minimum
 * than a note: a note queued before the burst has gone out would overwrite it.
 */
enum puck_chime_id {
	PUCK_CHIME_WAKE,	/* QAM held, before the radio goes to BLE */
	PUCK_CHIME_DONGLE,	/* the mode chord, before rebooting as the dongle */
	PUCK_CHIME_PRO,		/* the mode chord, before rebooting as Pro */
	PUCK_CHIME_COUNT,
};

/* 2 gave every note a haptic. Version 1 records still load: see puck_melody.c. */
#define PUCK_CHIME_VERSION	2
#define PUCK_CHIME_MAX_NOTES	16
#define PUCK_CHIME_HZ_MIN	50
#define PUCK_CHIME_HZ_MAX	2000
#define PUCK_CHIME_MS_MIN	20
#define PUCK_CHIME_REST_MS_MIN	60
#define PUCK_CHIME_MS_MAX	1000
#define PUCK_CHIME_TOTAL_MS_MAX	4000	/* whatever follows waits for all of it */

/* The haptic a note plays on when it does not say. */
#define PUCK_CHIME_CHANNEL_DEFAULT	PUCK_HAPTIC_RUMBLE_R

struct puck_note {
	uint16_t hz;
	uint16_t ms;
	uint8_t haptic;		/* PUCK_HAPTIC_*; ignored for a rest */
	uint8_t reserved;
};

struct puck_chime {
	uint8_t version;
	uint8_t count;
	struct puck_note notes[PUCK_CHIME_MAX_NOTES];
};

/* The haptics a note may play on, the default first. Returns how many. */
size_t puck_chime_channels(const uint8_t **list);

/* A chime's name in the config protocol, or NULL for an id out of range. */
const char *puck_chime_name(int id);

/* The id for a name, or -1. */
int puck_chime_lookup(const char *name);

/* Load every stored chime, or its default. The store must be mounted. */
void puck_chime_init(void);

/* A chime as it will play, or NULL for an id out of range. */
const struct puck_chime *puck_chime_get(int id);

/* Fill *c with a chime's default. */
void puck_chime_defaults(int id, struct puck_chime *c);

/* Check a chime against the limits. Returns 0, or -EINVAL with a reason in err
 * (which may be NULL).
 */
int puck_chime_check(const struct puck_chime *c, char *err, size_t errlen);

/* Parse "hz:ms[:haptic] ..." into *c and check it. A note without a haptic
 * plays on the default. Returns 0, or -EINVAL with a reason in err.
 */
int puck_chime_parse(const char *s, struct puck_chime *c, char *err,
		     size_t errlen);

/* Make *c a chime and persist it. Returns 0, -EINVAL for a bad id or a chime
 * that fails the checks, or -EIO if it could not be saved (it still plays until
 * reboot).
 */
int puck_chime_set(int id, const struct puck_chime *c);

/* chime.volume as a tone gain, shared by every chime: 0 is silent, 100 the
 * loudest that played clean.
 */
int8_t puck_chime_gain(void);

/*
 * Play a chime on a slot at a gain, then call done() from the system work queue
 * once its last stop has left. The chime is planned into commands before this
 * returns, so *c may change afterwards. Returns 0 if it started, or -EBUSY
 * while a chime is already playing, in which case done() is never called.
 *
 * RF has to own the radio for the whole chime: nothing reaches the controller
 * over BLE.
 */
int puck_melody_play(int slot, const struct puck_chime *c, int8_t gain,
		     void (*done)(void));

/* A stored chime at the configured volume. -EINVAL for an id out of range. */
int puck_melody_play_chime(int id, int slot, void (*done)(void));

/* The wake chime at the configured volume. */
int puck_melody_play_wake(int slot, void (*done)(void));

/* Whether a chime is playing. */
bool puck_melody_busy(void);

#endif /* PUCK_MELODY_H */
```

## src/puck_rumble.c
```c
/*
 * HD rumble decode. See puck_rumble.h for the shape of the problem.
 */

#include <zephyr/kernel.h>
#include <math.h>

#include "puck_rumble.h"
#include "puck_usb.h"

/* -8.0 log2 units: silent. Amplitudes live in [HDR_AMP_MIN, 0]. */
#define HDR_AMP_MIN (-256)
#define HDR_AMP_OFF (-256)

/* exp2(units/32) scaled to a 16-bit motor level, built once at boot. The two
 * lowest steps are treated as silent (the curve floors out there), which is
 * what makes an idle frame, decoding to minimum amplitude. Read as off.
 */
static uint16_t g_level[257];

/* Per-slot, per-motor (0 = left, 1 = right) running band amplitudes. The packed
 * 5-bit commands are RELATIVE, so this state must persist between frames.
 */
struct hdr_bands {
	int16_t lo;
	int16_t hi;
};

static struct hdr_bands g_state[PUCK_HID_SLOTS][2];

void puck_rumble_init(void)
{
	for (int u = HDR_AMP_MIN; u <= 0; u++) {
		float lin = (float)u / 32.0f;
		float amp = (lin >= -7.9375f) ? exp2f(lin) : 0.0f;
		uint32_t v;

		if (amp > 1.0f) {
			amp = 1.0f;
		}
		v = (uint32_t)(amp * 65535.0f + 0.5f);
		g_level[u - HDR_AMP_MIN] = (v > 0xFFFF) ? 0xFFFF : (uint16_t)v;
	}

	for (int s = 0; s < PUCK_HID_SLOTS; s++) {
		puck_rumble_reset(s);
	}
}

void puck_rumble_reset(int slot)
{
	if (slot < 0 || slot >= PUCK_HID_SLOTS) {
		return;
	}
	g_state[slot][0].lo = g_state[slot][0].hi = HDR_AMP_OFF;
	g_state[slot][1].lo = g_state[slot][1].hi = HDR_AMP_OFF;
}

/* Absolute 7-bit amplitude, in 1/32 log2 units. Three slopes. */
static int16_t amp7(uint8_t code)
{
	if (code == 0) {
		return HDR_AMP_MIN;
	}
	if (code < 16) {
		return (int16_t)(8 * (int)code - 248);	/* slope 1/4 */
	}
	if (code < 32) {
		return (int16_t)(2 * (int)code - 158);	/* slope 1/16 */
	}
	return (int16_t)((int)code - 127);		/* slope 1/32 */
}

/*
 * Apply a compact 5-bit command to a running amplitude:
 *   0        silence
 *   1..11    substitute an absolute preset: 0, -0.5, -1.0 ... -5.0
 *   17..22   step up   (+0.125 for 17-19, +0.03125 for 20-22)
 *   26..31   step down (-0.03125 for 26-28, -0.125 for 29-31)
 *   other    amplitude unchanged. The code carries only a frequency command
 */
static int16_t amp5(uint8_t code, int16_t cur)
{
	int step = 0;
	int v;

	if (code == 0) {
		return HDR_AMP_OFF;
	}
	if (code <= 11) {
		return (int16_t)(-16 * (int)(code - 1));
	}
	if (code >= 17 && code <= 19) {
		step = 4;
	} else if (code >= 20 && code <= 22) {
		step = 1;
	} else if (code >= 26 && code <= 28) {
		step = -1;
	} else if (code >= 29 && code <= 31) {
		step = -4;
	}
	v = (int)cur + step;
	return v < HDR_AMP_MIN ? HDR_AMP_MIN : (v > 0 ? 0 : (int16_t)v);
}

/* Pull a bit-field out of the 32-bit rumble word. */
static uint8_t field(uint32_t w, uint8_t shift, uint8_t width)
{
	return (uint8_t)((w >> shift) & ((1u << width) - 1u));
}

uint16_t puck_rumble_decode(int slot, int motor, const uint8_t b[4])
{
	struct hdr_bands *s;
	uint32_t w;
	uint16_t peak = 0;

	if (slot < 0 || slot >= PUCK_HID_SLOTS || motor < 0 || motor > 1) {
		return 0;
	}
	s = &g_state[slot][motor];
	w = (uint32_t)b[0] | ((uint32_t)b[1] << 8) | ((uint32_t)b[2] << 16) |
	    ((uint32_t)b[3] << 24);

#define SAMPLE()                                                     \
	do {                                                         \
		uint16_t la = g_level[s->lo - HDR_AMP_MIN];          \
		uint16_t ha = g_level[s->hi - HDR_AMP_MIN];          \
		uint16_t lv = la > ha ? la : ha;                     \
		if (lv > peak) {                                     \
			peak = lv;                                   \
		}                                                    \
	} while (0)

	switch (field(w, 30, 2)) {
	case 0:		/* hold */
		SAMPLE();
		break;
	case 1:
		if ((w & 0xFFFFF) == 0) {		/* one 5-bit update */
			s->lo = amp5(field(w, 25, 5), s->lo);
			s->hi = amp5(field(w, 20, 5), s->hi);
			SAMPLE();
		} else if ((w & 0x3) == 0) {		/* one 7-bit absolute */
			s->lo = amp7(field(w, 23, 7));
			s->hi = amp7(field(w, 9, 7));
			SAMPLE();
		} else {	/* 7-bit for one band, then two 5-bit updates */
			bool want_hi = (w & 1) != 0;
			bool is_freq = ((w >> 2) & 1) != 0;

			if (!is_freq) {		/* else it is a frequency: ignore */
				if (want_hi) {
					s->hi = amp7(field(w, 23, 7));
				} else {
					s->lo = amp7(field(w, 23, 7));
				}
			}
			SAMPLE();
			s->lo = amp5(field(w, 18, 5), s->lo);
			s->hi = amp5(field(w, 13, 5), s->hi);
			SAMPLE();
			s->lo = amp5(field(w, 8, 5), s->lo);
			s->hi = amp5(field(w, 3, 5), s->hi);
			SAMPLE();
		}
		break;
	case 2:
		if ((w & 0x3FF) == 0) {			/* two 5-bit updates */
			s->lo = amp5(field(w, 25, 5), s->lo);
			s->hi = amp5(field(w, 20, 5), s->hi);
			SAMPLE();
			s->lo = amp5(field(w, 15, 5), s->lo);
			s->hi = amp5(field(w, 10, 5), s->hi);
			SAMPLE();
		} else {		/* 7-bit + 5-bit, then a 5-bit update */
			if (w & 1) {
				s->hi = amp7(field(w, 23, 7));
				s->lo = amp5(field(w, 18, 5), s->lo);
			} else {
				s->lo = amp7(field(w, 23, 7));
				s->hi = amp5(field(w, 18, 5), s->hi);
			}
			SAMPLE();
			s->lo = amp5(field(w, 13, 5), s->lo);
			s->hi = amp5(field(w, 8, 5), s->hi);
			SAMPLE();
		}
		break;
	case 3:						/* three 5-bit updates */
		s->lo = amp5(field(w, 25, 5), s->lo);
		s->hi = amp5(field(w, 20, 5), s->hi);
		SAMPLE();
		s->lo = amp5(field(w, 15, 5), s->lo);
		s->hi = amp5(field(w, 10, 5), s->hi);
		SAMPLE();
		s->lo = amp5(field(w, 5, 5), s->lo);
		s->hi = amp5(field(w, 0, 5), s->hi);
		SAMPLE();
		break;
	}
#undef SAMPLE

	return peak;
}
```

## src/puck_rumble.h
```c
/*
 * Nintendo HD rumble, decoded into something a Steam Controller can feel.
 *
 * The console does not send "motor at 60%". It sends a packed, RELATIVE stream:
 * four bytes per motor per frame, carrying amplitude commands in 1/32 log2
 * units that step a running state up and down, with occasional absolute
 * presets. So the decode is stateful (frames only make sense in sequence)
 * and it has to run for every frame even when nothing is relayed onward.
 *
 * Ported from the Arduino build's mode_switch_pro.cpp, which measured all of
 * this against real hardware.
 */

#ifndef PUCK_RUMBLE_H
#define PUCK_RUMBLE_H

#include <stdint.h>

/* Build the exp2 level table. Call once at boot. */
void puck_rumble_init(void);

/* Forget a slot's running amplitudes, on a fresh host handshake where the
 * relative stream restarts and stale state would decode as noise.
 */
void puck_rumble_reset(int slot);

/*
 * Decode one motor's four rumble bytes, advancing that motor's state, and
 * return the PEAK motor level across the frame's updates.
 *
 * Peak rather than the final sample: a frame can pack three updates, and a
 * short pulse living in the middle of one would vanish if only the last were
 * taken. Idle and neutral frames still resolve to 0.
 */
uint16_t puck_rumble_decode(int slot, int motor, const uint8_t b[4]);

#endif /* PUCK_RUMBLE_H */
```
